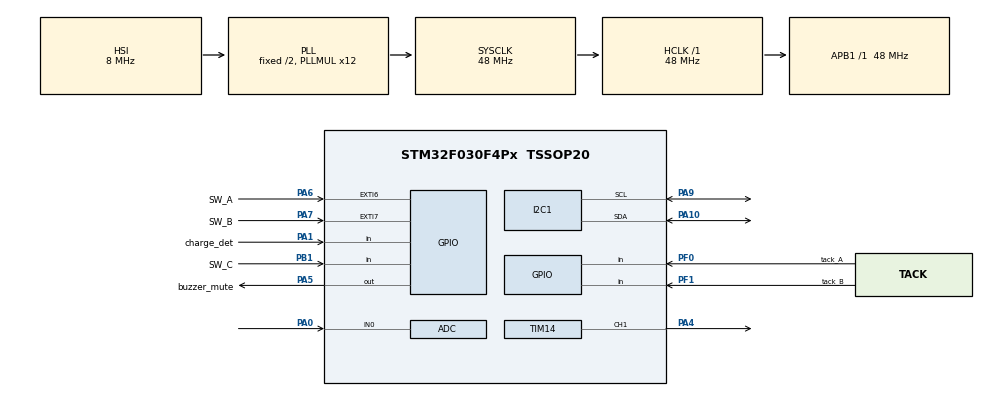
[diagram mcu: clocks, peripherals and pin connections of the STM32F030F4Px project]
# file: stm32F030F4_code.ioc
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Mcu.Family=STM32F0
Mcu.Name=STM32F030F4Px
Mcu.Package=TSSOP20
PA0.Mode=IN0
PA0.Signal=ADC_IN0
PA1.GPIO_Label=charge_det
PA1.Signal=GPIO_Input
PA10.Mode=I2C
PA10.Signal=I2C1_SDA
PA4.Signal=S_TIM14_CH1
PA5.GPIO_Label=buzzer_mute
PA5.Signal=GPIO_Output
PA6.GPIO_Label=SW_A
PA6.Signal=GPXTI6
PA7.GPIO_Label=SW_B
PA7.Signal=GPXTI7
PA9.Mode=I2C
PA9.Signal=I2C1_SCL
PB1.GPIO_Label=SW_C
PB1.GPIO_PuPd=GPIO_PULLUP
PB1.Signal=GPIO_Input
PF0-OSC_IN.GPIO_Label=tack_A
PF0-OSC_IN.GPIO_PuPd=GPIO_PULLUP
PF0-OSC_IN.Signal=GPIO_Input
PF1-OSC_OUT.GPIO_Label=tack_B
PF1-OSC_OUT.GPIO_PuPd=GPIO_PULLUP
PF1-OSC_OUT.Signal=GPIO_Input
ProjectManager.HeapSize=0x200
ProjectManager.StackSize=0x400
ProjectManager.TargetToolchain=STM32CubeIDE
RCC.AHBFreq_Value=48000000
RCC.APB1Freq_Value=48000000
RCC.APB1TimFreq_Value=48000000
RCC.HCLKFreq_Value=48000000
RCC.PLLMUL=RCC_PLL_MUL12
RCC.SYSCLKFreq_VALUE=48000000
RCC.SYSCLKSource=RCC_SYSCLKSOURCE_PLLCLK
SH.S_TIM14_CH1.0=TIM14_CH1,PWM Generation1 CH1
TIM14.Channel=TIM_CHANNEL_1
VP_TIM14_VS_ClockSourceINT.Mode=Enable_Timer
board=custom

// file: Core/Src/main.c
/* USER CODE BEGIN Header */
/**
  ******************************************************************************
  * @file           : main.c
  * @brief          : Main program body
  ******************************************************************************
  * @attention
  *
  * <h2><center>&copy; Copyright (c) 2022 STMicroelectronics.
  * All rights reserved.</center></h2>
  *
  * This software component is licensed by ST under BSD 3-Clause license,
  * the "License"; You may not use this file except in compliance with the
  * License. You may obtain a copy of the License at:
  *                        opensource.org/licenses/BSD-3-Clause
  *
  ******************************************************************************
  */
/* USER CODE END Header */
#include "main.h"

/* USER CODE BEGIN Includes */
#include "my.h"
/* USER CODE END Includes */

 ADC_HandleTypeDef hadc;

I2C_HandleTypeDef hi2c1;

TIM_HandleTypeDef htim14;

void SystemClock_Config(void);
static void MX_GPIO_Init(void);
static void MX_ADC_Init(void);
static void MX_I2C1_Init(void);
static void MX_TIM14_Init(void);

int main(void)
{

  /* MCU Configuration--------------------------------------------------------*/

  /* Reset of all peripherals, Initializes the Flash interface and the Systick. */
  HAL_Init();

  /* Configure the system clock */
  SystemClock_Config();

  /* Initialize all configured peripherals */
  MX_GPIO_Init();
  MX_ADC_Init();
  MX_I2C1_Init();
  MX_TIM14_Init();
  /* USER CODE BEGIN 2 */
  mymain();
  /* USER CODE END 2 */

  /* Infinite loop */
  while (1)
  {

  }
}

void SystemClock_Config(void)
{
  RCC_OscInitTypeDef RCC_OscInitStruct = {0};
  RCC_ClkInitTypeDef RCC_ClkInitStruct = {0};
  RCC_PeriphCLKInitTypeDef PeriphClkInit = {0};

  /** Initializes the RCC Oscillators according to the specified parameters
  * in the RCC_OscInitTypeDef structure.
  */
  RCC_OscInitStruct.OscillatorType = RCC_OSCILLATORTYPE_HSI|RCC_OSCILLATORTYPE_HSI14;
  RCC_OscInitStruct.HSIState = RCC_HSI_ON;
  RCC_OscInitStruct.HSI14State = RCC_HSI14_ON;
  RCC_OscInitStruct.HSICalibrationValue = RCC_HSICALIBRATION_DEFAULT;
  RCC_OscInitStruct.HSI14CalibrationValue = 16;
  RCC_OscInitStruct.PLL.PLLState = RCC_PLL_ON;
  RCC_OscInitStruct.PLL.PLLSource = RCC_PLLSOURCE_HSI;
  RCC_OscInitStruct.PLL.PLLMUL = RCC_PLL_MUL12;
  RCC_OscInitStruct.PLL.PREDIV = RCC_PREDIV_DIV1;
  if (HAL_RCC_OscConfig(&RCC_OscInitStruct) != HAL_OK)
  {
    Error_Handler();
  }

  /** Initializes the CPU, AHB and APB buses clocks
  */
  RCC_ClkInitStruct.ClockType = RCC_CLOCKTYPE_HCLK|RCC_CLOCKTYPE_SYSCLK
                              |RCC_CLOCKTYPE_PCLK1;
  RCC_ClkInitStruct.SYSCLKSource = RCC_SYSCLKSOURCE_PLLCLK;
  RCC_ClkInitStruct.AHBCLKDivider = RCC_SYSCLK_DIV1;
  RCC_ClkInitStruct.APB1CLKDivider = RCC_HCLK_DIV1;

  if (HAL_RCC_ClockConfig(&RCC_ClkInitStruct, FLASH_LATENCY_1) != HAL_OK)
  {
    Error_Handler();
  }
  PeriphClkInit.PeriphClockSelection = RCC_PERIPHCLK_I2C1;
  PeriphClkInit.I2c1ClockSelection = RCC_I2C1CLKSOURCE_HSI;
  if (HAL_RCCEx_PeriphCLKConfig(&PeriphClkInit) != HAL_OK)
  {
    Error_Handler();
  }
}

static void MX_ADC_Init(void)
{

  ADC_ChannelConfTypeDef sConfig = {0};

  /** Configure the global features of the ADC (Clock, Resolution, Data Alignment and number of conversion)
  */
  hadc.Instance = ADC1;
  hadc.Init.ClockPrescaler = ADC_CLOCK_ASYNC_DIV1;
  hadc.Init.Resolution = ADC_RESOLUTION_12B;
  hadc.Init.DataAlign = ADC_DATAALIGN_RIGHT;
  hadc.Init.ScanConvMode = ADC_SCAN_DIRECTION_FORWARD;
  hadc.Init.EOCSelection = ADC_EOC_SINGLE_CONV;
  hadc.Init.LowPowerAutoWait = DISABLE;
  hadc.Init.LowPowerAutoPowerOff = DISABLE;
  hadc.Init.ContinuousConvMode = DISABLE;
  hadc.Init.DiscontinuousConvMode = DISABLE;
  hadc.Init.ExternalTrigConv = ADC_SOFTWARE_START;
  hadc.Init.ExternalTrigConvEdge = ADC_EXTERNALTRIGCONVEDGE_NONE;
  hadc.Init.DMAContinuousRequests = DISABLE;
  hadc.Init.Overrun = ADC_OVR_DATA_PRESERVED;
  if (HAL_ADC_Init(&hadc) != HAL_OK)
  {
    Error_Handler();
  }

  /** Configure for the selected ADC regular channel to be converted.
  */
  sConfig.Channel = ADC_CHANNEL_0;
  sConfig.Rank = ADC_RANK_CHANNEL_NUMBER;
  sConfig.SamplingTime = ADC_SAMPLETIME_1CYCLE_5;
  if (HAL_ADC_ConfigChannel(&hadc, &sConfig) != HAL_OK)
  {
    Error_Handler();
  }

}

static void MX_I2C1_Init(void)
{

  hi2c1.Instance = I2C1;
  hi2c1.Init.Timing = 0x2000090E;
  hi2c1.Init.OwnAddress1 = 0;
  hi2c1.Init.AddressingMode = I2C_ADDRESSINGMODE_7BIT;
  hi2c1.Init.DualAddressMode = I2C_DUALADDRESS_DISABLE;
  hi2c1.Init.OwnAddress2 = 0;
  hi2c1.Init.OwnAddress2Masks = I2C_OA2_NOMASK;
  hi2c1.Init.GeneralCallMode = I2C_GENERALCALL_DISABLE;
  hi2c1.Init.NoStretchMode = I2C_NOSTRETCH_DISABLE;
  if (HAL_I2C_Init(&hi2c1) != HAL_OK)
  {
    Error_Handler();
  }

  /** Configure Analogue filter
  */
  if (HAL_I2CEx_ConfigAnalogFilter(&hi2c1, I2C_ANALOGFILTER_ENABLE) != HAL_OK)
  {
    Error_Handler();
  }

  /** Configure Digital filter
  */
  if (HAL_I2CEx_ConfigDigitalFilter(&hi2c1, 0) != HAL_OK)
  {
    Error_Handler();
  }

}

static void MX_TIM14_Init(void)
{

  TIM_OC_InitTypeDef sConfigOC = {0};

  htim14.Instance = TIM14;
  htim14.Init.Prescaler = 0;
  htim14.Init.CounterMode = TIM_COUNTERMODE_UP;
  htim14.Init.Period = 65535;
  htim14.Init.ClockDivision = TIM_CLOCKDIVISION_DIV1;
  htim14.Init.AutoReloadPreload = TIM_AUTORELOAD_PRELOAD_DISABLE;
  if (HAL_TIM_Base_Init(&htim14) != HAL_OK)
  {
    Error_Handler();
  }
  if (HAL_TIM_PWM_Init(&htim14) != HAL_OK)
  {
    Error_Handler();
  }
  sConfigOC.OCMode = TIM_OCMODE_PWM1;
  sConfigOC.Pulse = 0;
  sConfigOC.OCPolarity = TIM_OCPOLARITY_HIGH;
  sConfigOC.OCFastMode = TIM_OCFAST_DISABLE;
  if (HAL_TIM_PWM_ConfigChannel(&htim14, &sConfigOC, TIM_CHANNEL_1) != HAL_OK)
  {
    Error_Handler();
  }
  HAL_TIM_MspPostInit(&htim14);

}

static void MX_GPIO_Init(void)
{
  GPIO_InitTypeDef GPIO_InitStruct = {0};

  /* GPIO Ports Clock Enable */
  __HAL_RCC_GPIOF_CLK_ENABLE();
  __HAL_RCC_GPIOA_CLK_ENABLE();
  __HAL_RCC_GPIOB_CLK_ENABLE();

  /*Configure GPIO pin Output Level */
  HAL_GPIO_WritePin(buzzer_mute_GPIO_Port, buzzer_mute_Pin, GPIO_PIN_RESET);

  /*Configure GPIO pins : tack_A_Pin tack_B_Pin */
  GPIO_InitStruct.Pin = tack_A_Pin|tack_B_Pin;
  GPIO_InitStruct.Mode = GPIO_MODE_INPUT;
  GPIO_InitStruct.Pull = GPIO_PULLUP;
  HAL_GPIO_Init(GPIOF, &GPIO_InitStruct);

  /*Configure GPIO pin : charge_det_Pin */
  GPIO_InitStruct.Pin = charge_det_Pin;
  GPIO_InitStruct.Mode = GPIO_MODE_INPUT;
  GPIO_InitStruct.Pull = GPIO_NOPULL;
  HAL_GPIO_Init(charge_det_GPIO_Port, &GPIO_InitStruct);

  /*Configure GPIO pin : buzzer_mute_Pin */
  GPIO_InitStruct.Pin = buzzer_mute_Pin;
  GPIO_InitStruct.Mode = GPIO_MODE_OUTPUT_PP;
  GPIO_InitStruct.Pull = GPIO_NOPULL;
  GPIO_InitStruct.Speed = GPIO_SPEED_FREQ_LOW;
  HAL_GPIO_Init(buzzer_mute_GPIO_Port, &GPIO_InitStruct);

  /*Configure GPIO pins : SW_A_Pin SW_B_Pin */
  GPIO_InitStruct.Pin = SW_A_Pin|SW_B_Pin;
  GPIO_InitStruct.Mode = GPIO_MODE_IT_RISING;
  GPIO_InitStruct.Pull = GPIO_NOPULL;
  HAL_GPIO_Init(GPIOA, &GPIO_InitStruct);

  /*Configure GPIO pin : SW_C_Pin */
  GPIO_InitStruct.Pin = SW_C_Pin;
  GPIO_InitStruct.Mode = GPIO_MODE_INPUT;
  GPIO_InitStruct.Pull = GPIO_PULLUP;
  HAL_GPIO_Init(SW_C_GPIO_Port, &GPIO_InitStruct);

}

void Error_Handler(void)
{
  __disable_irq();
  while (1)
  {
  }
}
